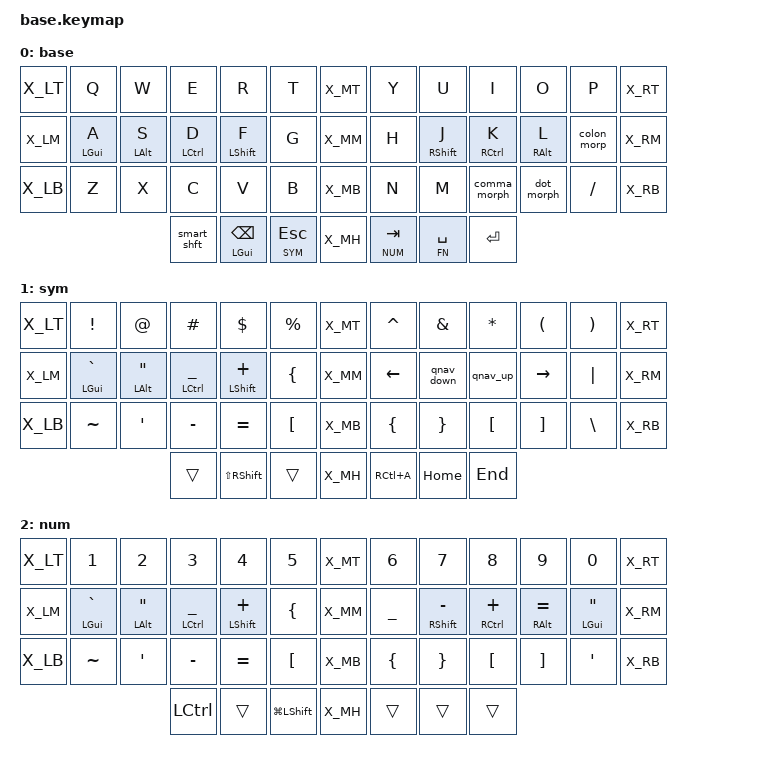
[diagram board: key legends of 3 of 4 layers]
#include <behaviors.dtsi>
#include <dt-bindings/zmk/keys.h>
#if CONFIG_WIRELESS
    #include <dt-bindings/zmk/bt.h>
    #define _BT_SEL_KEYS_ &bt BT_CLR &bt BT_SEL 0 &bt BT_SEL 1 &bt BT_SEL 2 &bt BT_SEL 3
#else
    #define _BT_SEL_KEYS_ &trans &trans &trans &trans &trans
#endif

#include <dt-bindings/zmk/outputs.h>
#include "../zmk-nodefree-config/helper.h"

#define DEF 0
#define SYM 1
#define NUM 2
#define FN 3
// #define MOUSE 7


// #include "mouse.dtsi"
#include "extra_keys.h"

#define XXX &none
#define ___ &trans

/* Global settings */

#define QUICK_TAP_MS 75

&sk {  // sticky-key config
    release-after-ms = <900>;  // release after 0.6s
    quick-release;             // no double capitalization when rolling keys
};

&sl {  // sticky-layer config
    ignore-modifiers;          // allow chording sticky mods & layers
};

&lt {  // layer-tap config
    flavor = "tap-preferred";
    tapping-term-ms = <150>;
    quick-tap-ms = <QUICK_TAP_MS>;
};

//ZMK_CONDITIONAL_LAYER(FN NUM, SYS)  // FN + NUM --> SYS


/* Homerow mods */

#define KEYS_L LT0 LT1 LT2 LT3 LT4 LM0 LM1 LM2 LM3 LM4 LB0 LB1 LB2 LB3 LB4  // left hand
#define KEYS_R RT0 RT1 RT2 RT3 RT4 RM0 RM1 RM2 RM3 RM4 RB0 RB1 RB2 RB3 RB4  // right hand
#define THUMBS LH2 LH1 LH0 RH0 RH1 RH2                                      // thumbs

#define MAKE_HRM(NAME, HOLD, TAP, TRIGGER_POS) \
    ZMK_BEHAVIOR(NAME, hold_tap, \
        flavor = "balanced"; \
        tapping-term-ms = <280>; \
        quick-tap-ms = <QUICK_TAP_MS>; \
        require-prior-idle-ms = <150>; \
        bindings = <HOLD>, <TAP>; \
        hold-trigger-key-positions = <TRIGGER_POS>; \
        hold-trigger-on-release; \
    )
MAKE_HRM(hml, &kp, &kp, KEYS_R THUMBS)  // left-hand HRMs
MAKE_HRM(hmr, &kp, &kp, KEYS_L THUMBS)  // right-hand HRMs

MAKE_HRM(hml_repeat, &kp, &key_repeat, KEYS_R THUMBS)  // used for HRM-combo
MAKE_HRM(hmr_lpar_lt, &kp, &lpar_lt, KEYS_R THUMBS)    // "    "   "   "
MAKE_HRM(hmr_rpar_gt, &kp, &rpar_gt, KEYS_R THUMBS)    // "    "   "   "

/* Nav cluster */

// long-tap action on hold, short-tap action on all interrupts
#define MT_CORE \
    flavor = "tap-preferred"; \
    tapping-term-ms = <150>; \
    quick-tap-ms = <QUICK_TAP_MS>;

&mt { MT_CORE };

#define NAV_LEFT  &kp LEFT    // tap: left  | long-tap: beginning of line
#define NAV_RIGHT &kp RIGHT   // tap: right | long-tap: end       of line
#define NAV_UP    &mt LC(HOME) UP      // tap: up    | long-tap: beginning of document
#define NAV_DOWN  &mt LC(END)  DOWN    // tap: down  | long-tap: end       of document
#define NAV_BSPC  &mt LC(BSPC) BSPC    // tap: bspc  | long-tap: delete word backward
#define NAV_DEL   &mt LC(DEL)  DEL     // tap: del   | long-tap: delete word forward

/* Caps-word, num-word and smart-mouse */

// tap: sticky-shift | shift + tap/ double-tap: caps-word | hold: shift
ZMK_BEHAVIOR(smart_shft, mod_morph,
    bindings = <&sk LSHFT>, <&caps_word>;
    mods = <(MOD_LSFT)>;
)
&caps_word {  // mods deactivate caps-word, requires PR #1451
    /delete-property/ ignore-modifiers;
};

// smart-mouse, requires PR #1366
// ZMK_BEHAVIOR(smart_mouse, tri_state,
//    bindings = <&tog MOUSE>, <&none>, <&tog MOUSE>;
//    ignored-key-positions = <LT1 LT3 RT0 RT1 RT2 RT3 RT4 RM1 RM2 RM3 RB1 RB2 RB3 RH0 RH1>;
//    ignored-layers = <MOUSE>;
// )

// reuse basic mod-morph scheme
#define SIMPLE_MORPH(NAME, MOD, BINDING1, BINDING2) \
    ZMK_BEHAVIOR(NAME, mod_morph, \
        mods = <(MOD_L ## MOD|MOD_R ## MOD)>; \
        bindings = <BINDING1>, <BINDING2>; \
    )

// tap: comma | shift + tap: semicolon | ctrl + shift + tap: <
SIMPLE_MORPH(comma_morph, SFT, &kp COMMA, &comma_inner_morph)
SIMPLE_MORPH(comma_inner_morph, CTL, &kp LESS_THAN, &kp SEMICOLON)

// tap: dot | shift + tap: colon | ctrl + shift + tap: >
SIMPLE_MORPH(dot_morph, SFT, &kp DOT, &dot_inner_morph)
SIMPLE_MORPH(dot_inner_morph, CTL, &kp GREATER_THAN, &kp COLON)


SIMPLE_MORPH(colon_morp, SFT, &hmr LGUI SEMICOLON, &colon_inner_morph)
SIMPLE_MORPH(colon_inner_morph, CTL, &kp COLON, &kp EQUAL)

// tap: left/right parenthesis | shft + tap: less-than/greater-than
SIMPLE_MORPH(lpar_lt, SFT, &kp LPAR, &kp LT)
SIMPLE_MORPH(rpar_gt, SFT, &kp RPAR, &kp GT)

ZMK_BEHAVIOR(nav_5_down, macro,
    wait-ms = <5>;
    tap-ms = <3>;   
    bindings = <&kp DOWN>, <&kp DOWN>, <&kp DOWN>, <&kp DOWN>, <&kp DOWN>;
)
ZMK_BEHAVIOR(nav_5_up, macro,
    wait-ms = <5>;
    tap-ms = <3>;
    bindings = <&kp UP>, <&kp UP>, <&kp UP>, <&kp UP>, <&kp UP>;
)
SIMPLE_MORPH(qnav_down, ALT, &kp DOWN, &nav_5_down)
SIMPLE_MORPH(qnav_up, ALT, &kp UP, &nav_5_up)
      

/* Keymap */

ZMK_LAYER(base,
//╭──────╮ ╭─────────────┬─────────────┬─────────────┬─────────────┬─────────────╮ ╭──────╮ ╭─────────────┬─────────────┬─────────────┬─────────────┬─────────────╮ ╭──────╮
    X_LT     &kp Q         &kp W         &kp E         &kp R         &kp T           X_MT     &kp Y         &kp U         &kp I         &kp O         &kp P           X_RT
//├──────┤ ├─────────────┼─────────────┼─────────────┼─────────────┼─────────────┤ ├──────┤ ├─────────────┼─────────────┼─────────────┼─────────────┼─────────────┤ ├──────┤
    X_LM     &hml LGUI A  &hml LALT S   &hml LCTRL D   &hml LSHFT F  &kp G           X_MM     &kp H         &hmr RSHFT J  &hmr RCTRL K   &hmr RALT L  &colon_morp      X_RM
//├──────┤ ├─────────────┼─────────────┼─────────────┼─────────────┼─────────────┤ ├──────┤ ├─────────────┼─────────────┼─────────────┼─────────────┼─────────────┤ ├──────┤
    X_LB     &kp Z         &kp X         &kp C         &kp V         &kp B           X_MB     &kp N         &kp M         &comma_morph  &dot_morph    &kp FSLH        X_RB
//╰──────╯ ╰───────────────────────────┴─────────────┼─────────────┼─────────────┤ ├──────┤ ├─────────────┼─────────────┼─────────────┴───────────────────────────╯ ╰──────╯
                                         &smart_shft   &mt LGUI BSPC  &lt SYM ESC    X_MH     &lt NUM TAB   &lt FN SPACE  &kp RETURN
//                                     ╰─────────────┴─────────────┴─────────────╯ ╰──────╯ ╰─────────────┴─────────────┴─────────────╯
)


 ZMK_LAYER(sym,
//╭──────╮ ╭─────────────────┬────────────────┬──────────────────┬──────────────────┬────────────╮ ╭──────╮ ╭─────────────┬─────────────┬─────────────┬─────────────┬─────────────╮ ╭──────╮
    X_LT     &kp EXCL          &kp AT           &kp HASH            &kp DLLR          &kp PRCNT      X_MT     &kp CARET     &kp AMPS       &kp STAR     &kp LPAR      &kp RPAR        X_RT
//├──────┤ ├─────────────────┼────────────────┼──────────────────┼──────────────────┼────────────┤ ├──────┤ ├─────────────┼─────────────┼─────────────┼─────────────┼─────────────┤ ├──────┤
    X_LM     &hml LGUI GRAVE   &hml LALT DQT    &hml LCTRL UNDER   &hml LSHFT PLUS    &kp LBRC       X_MM     NAV_LEFT      &qnav_down     &qnav_up     NAV_RIGHT     &kp PIPE        X_RM
//├──────┤ ├─────────────────┼────────────────┼──────────────────┼──────────────────┼────────────┤ ├──────┤ ├─────────────┼─────────────┼─────────────┼─────────────┼─────────────┤ ├──────┤
    X_LB     &kp TILDE         &kp SQT          &kp MINUS          &kp EQUAL          &kp LBKT       X_MB     &kp LBRC      &kp RBRC      &kp LBKT      &kp RBKT      &kp BSLH        X_RB
//╰──────╯ ╰─────────────────┼────────────────┴──────────────────┼──────────────────┼────────────┤ ├──────┤ ├─────────────┼─────────────┼─────────────┴───────────────────────────╯ ╰──────╯
                                                        ___          &kp LS(RSHIFT)     ___          X_MH     &kp RC(A)     &kp HOME      &kp END  
//                                            ╰──────────────────┴──────────────────┴────────────╯ ╰──────╯ ╰─────────────┴─────────────┴─────────────╯
)


ZMK_LAYER(num,
//╭──────╮ ╭─────────────────┬────────────────┬───────────────────┬──────────────────┬────────────────╮ ╭──────╮ ╭─────────────┬──────────────────┬────────────────┬────────────────┬───────────────╮ ╭──────╮
    X_LT     &kp N1            &kp N2            &kp N3             &kp N4              &kp N5            X_MT     &kp N6        &kp N7             &kp N8           &kp N9           &kp N0            X_RT
//├──────┤ ├─────────────────┼────────────────┼───────────────────┼──────────────────┼────────────────┤ ├──────┤ ├─────────────┼──────────────────┼────────────────┼────────────────┼───────────────┤ ├──────┤
    X_LM     &hml LGUI GRAVE   &hml LALT DQT     &hml LCTRL UNDER   &hml LSHFT PLUS     &kp LBRC          X_MM     &kp UNDER     &hmr RSHFT MINUS   &hmr RCTRL PLUS  &hmr RALT EQUAL  &hmr LGUI DQT    X_RM
//├──────┤ ├─────────────────┼────────────────┼───────────────────┼──────────────────┼────────────────┤ ├──────┤ ├─────────────┼──────────────────┼────────────────┼────────────────┼───────────────┤ ├──────┤
    X_LB     &kp TILDE         &kp SQT           &kp MINUS          &kp EQUAL           &kp LBKT          X_MB     &kp LBRC      &kp RBRC           &kp LBKT         &kp RBKT         &kp SQT          X_RB
//╰──────╯ ╰─────────────────┼────────────────┴───────────────────┼──────────────────┼────────────────┤ ├──────┤ ├─────────────┼──────────────────┼────────────────┴────────────────────────────────╯ ╰──────╯
                                                    &kp LCTRL          ___        &kp LG(LSHIFT)     X_MH       ___           ___           ___  
//                                            ╰───────────────────┴──────────────────┴────────────────╯ ╰──────╯ ╰─────────────┴──────────────────┴────────────────╯
)


ZMK_LAYER(fn,
//╭──────╮ ╭─────────────┬─────────────┬─────────────┬─────────────────┬──────────────────╮ ╭──────╮ ╭─────────────┬─────────────┬─────────────┬─────────────┬─────────────╮ ╭──────╮
    X_LT     &kp OUT_BLE   &kp OUT_USB   &kp LS(PSCRN) &kp PSCRN         &sk LG(LS(LCTRL))    X_MT     &kp F1        &kp F2         &kp F3        &kp F4       &kp F5          X_RT
//├──────┤ ├─────────────┼─────────────┼─────────────┼─────────────────┼──────────────────┤ ├──────┤ ├─────────────┼─────────────┼─────────────┼─────────────┼─────────────┤ ├──────┤
    X_LM     &sk LGUI      &sk LALT      &sk LCTRL     &sk LSHFT         &sk LC(LALT)         X_MM     &kp F6         &kp F7       &kp F8         &kp F9       &kp F10         X_RM
//├──────┤ ├─────────────┼─────────────┼─────────────┼─────────────────┼──────────────────┤ ├──────┤ ├─────────────┼─────────────┼─────────────┼─────────────┼─────────────┤ ├──────┤
    X_LB     _BT_SEL_KEYS_                                                                    X_MB     &kp F11       &kp F12       &kp K_PREV     &kp K_PP     &kp K_NEXT      X_RB
//╰──────╯ ╰─────────────┼─────────────┴─────────────┼─────────────────┼──────────────────┤ ├──────┤ ├─────────────┼─────────────┼─────────────┴───────────────────────────╯ ╰──────╯
                                          &kp K_MUTE  &kp C_VOLUME_DOWN  &kp C_VOLUME_UP      X_MH     ___           ___           ___
//                                     ╰─────────────┴─────────────────┴──────────────────╯ ╰──────╯ ╰─────────────┴─────────────┴─────────────╯
)

/*
ZMK_LAYER(fn,
//╭──────╮ ╭─────────────┬─────────────┬─────────────┬─────────────────┬──────────────────╮ ╭──────╮ ╭─────────────┬─────────────┬─────────────┬─────────────┬─────────────╮ ╭──────╮
    X_LT     &kp OUT_BLE   &kp OUT_USB   &kp LS(PSCRN) &kp PSCRN         &sk LG(LS(LCTRL))    X_MT     &kp F1        &kp F2         &kp F3        &kp F4       &kp F5          X_RT
//├──────┤ ├─────────────┼─────────────┼─────────────┼─────────────────┼──────────────────┤ ├──────┤ ├─────────────┼─────────────┼─────────────┼─────────────┼─────────────┤ ├──────┤
    X_LM     &sk LGUI      &sk LALT      &sk LCTRL     &sk LSHFT         &sk LC(LALT)         X_MM     &kp F6         &kp F7       &kp F8         &kp F9       &kp F10         X_RM
//├──────┤ ├─────────────┼─────────────┼─────────────┼─────────────────┼──────────────────┤ ├──────┤ ├─────────────┼─────────────┼─────────────┼─────────────┼─────────────┤ ├──────┤
    X_LB     _BT_SEL_KEYS_                                                                    X_MB     &kp F11       &kp F12       &kp K_PREV     &kp K_PP     &kp K_NEXT      X_RB
//╰──────╯ ╰─────────────┼─────────────┴─────────────┼─────────────────┼──────────────────┤ ├──────┤ ├─────────────┼─────────────┼─────────────┴───────────────────────────╯ ╰──────╯
                                          &kp K_MUTE  &kp C_VOLUME_DOWN  &kp C_VOLUME_UP      X_MH     ___           ___           ___
//                                     ╰─────────────┴─────────────────┴──────────────────╯ ╰──────╯ ╰─────────────┴─────────────┴─────────────╯
)

*/
// ZMK_LAYER(mouse,
//╭──────╮ ╭─────────────┬─────────────┬─────────────┬─────────────┬─────────────╮ ╭──────╮ ╭─────────────┬─────────────┬─────────────┬─────────────┬─────────────╮ ╭──────╮
//    X_LT     ___           ___           ___           ___           ___             X_MT     U_WH_L        U_WH_D        U_MS_U         U_WH_U       U_WH_R          X_RT
//├──────┤ ├─────────────┼─────────────┼─────────────┼─────────────┼─────────────┤ ├──────┤ ├─────────────┼─────────────┼─────────────┼─────────────┼─────────────┤ ├──────┤
//    X_LM     ___           ___           ___           ___           ___             X_MM     ___           U_MS_L        U_MS_D         U_MS_R       ___             X_RM
//├──────┤ ├─────────────┼─────────────┼─────────────┼─────────────┼─────────────┤ ├──────┤ ├─────────────┼─────────────┼─────────────┼─────────────┼─────────────┤ ├──────┤
//    X_LB     ___           ___           ___           ___           ___             X_MB     ___           &mkp MB4      &mkp MCLK      &mkp MB5     ___             X_RB
//├──────┤ ╰─────────────┼─────────────┴─────────────┼─────────────┼─────────────┤ ├──────┤ ├─────────────┼─────────────┼─────────────┴───────────────────────────╯ ├──────┤
//    X_LH                                               ___           ___             X_MH     &mkp LCLK     &mkp RCLK                                                 X_RH
//╰──────╯                                           ╰─────────────┴─────────────╯ ╰──────╯ ╰─────────────┴─────────────╯                                           ╰──────╯
//)

/* vim: set ft=c tw=174: */
